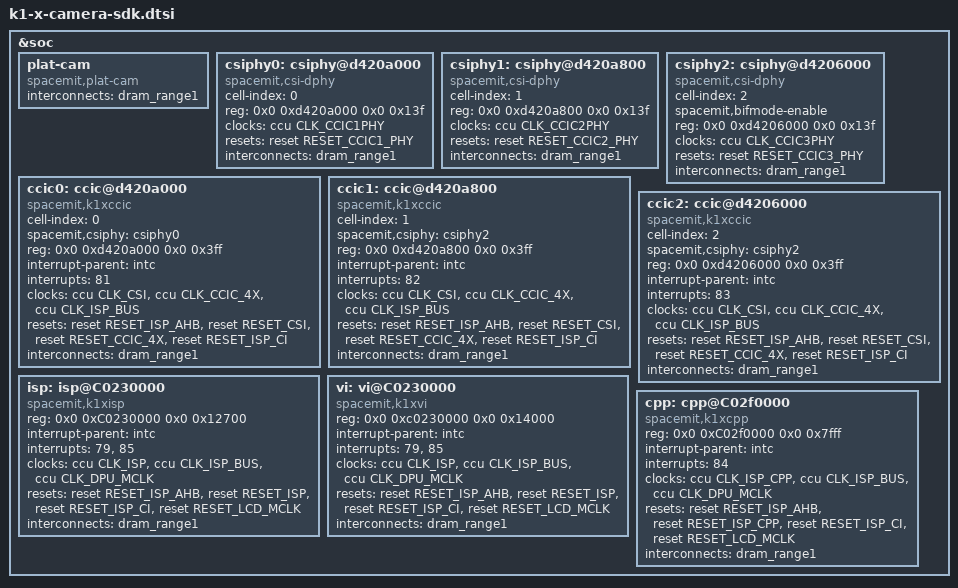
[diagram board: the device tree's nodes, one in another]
// SPDX-License-Identifier: GPL-2.0
/*
 * Copyright (C) 2023 SPACEMIT Micro Limited
 */

//#include "k1-x-camera-reserved-mm.dtsi"
#include "k1-x-camera-sensor.dtsi"

&soc {
	plat-cam {
		compatible = "spacemit,plat-cam", "simple-bus";
		#address-cells = <2>;
		#size-cells = <2>;
		interconnects = <&dram_range1>;
		interconnect-names = "dma-mem";
		status = "okay";
	};

	csiphy0: csiphy@d420a000 {
		compatible = "spacemit,csi-dphy";
		cell-index = <0>;
		reg = <0x0 0xd420a000 0x0 0x13f>;
		reg-names = "csiphy-regs";
		clocks = <&ccu CLK_CCIC1PHY>;
		clock-names = "csi_dphy";
		resets = <&reset RESET_CCIC1_PHY>;
		reset-names = "cphy_reset";
		interconnects = <&dram_range1>;
		interconnect-names = "dma-mem";
		status = "okay";
	};

	csiphy1: csiphy@d420a800 {
		compatible = "spacemit,csi-dphy";
		cell-index = <1>;
		reg = <0x0 0xd420a800 0x0 0x13f>;
		reg-names = "csiphy-regs";
		clocks = <&ccu CLK_CCIC2PHY>;
		clock-names = "csi_dphy";
		resets = <&reset RESET_CCIC2_PHY>;
		reset-names = "cphy_reset";
		interconnects = <&dram_range1>;
		interconnect-names = "dma-mem";
		status = "okay";
	};

	csiphy2: csiphy@d4206000 {
		compatible = "spacemit,csi-dphy";
		cell-index = <2>;
		spacemit,bifmode-enable;
		reg = <0x0 0xd4206000 0x0 0x13f>;
		reg-names = "csiphy-regs";
		clocks = <&ccu CLK_CCIC3PHY>;
		clock-names = "csi_dphy";
		resets = <&reset RESET_CCIC3_PHY>;
		reset-names = "cphy_reset";
		interconnects = <&dram_range1>;
		interconnect-names = "dma-mem";
		status = "okay";
	};

	ccic0: ccic@d420a000 {
		compatible = "spacemit,k1xccic";
		cell-index = <0>;
		spacemit,csiphy = <&csiphy0>;
		reg = <0x0 0xd420a000 0x0 0x3ff>;
		reg-names = "ccic-regs";
		interrupt-parent = <&intc>;
		interrupts = <81>;
		interrupt-names = "ipe-irq";
		clocks = <&ccu CLK_CSI>,
				<&ccu CLK_CCIC_4X>,
				<&ccu CLK_ISP_BUS>;
		clock-names = "csi_func", "ccic_func", "isp_axi";
		resets = <&reset RESET_ISP_AHB>, <&reset RESET_CSI>,
				<&reset RESET_CCIC_4X>, <&reset RESET_ISP_CI>;
		reset-names = "isp_ahb_reset", "csi_reset",
				"ccic_4x_reset", "isp_ci_reset";
		interconnects = <&dram_range1>;
		interconnect-names = "dma-mem";
		status = "okay";
	};

	ccic1: ccic@d420a800 {
		compatible = "spacemit,k1xccic";
		cell-index = <1>;
		spacemit,csiphy = <&csiphy2>;
		reg = <0x0 0xd420a800 0x0 0x3ff>;
		reg-names = "ccic-regs";
		interrupt-parent = <&intc>;
		interrupts = <82>;
		interrupt-names = "ipe-irq";
		clocks = <&ccu CLK_CSI>, <&ccu CLK_CCIC_4X>,
				<&ccu CLK_ISP_BUS>;
		clock-names = "csi_func", "ccic_func",
				"isp_axi";
		resets = <&reset RESET_ISP_AHB>, <&reset RESET_CSI>,
				<&reset RESET_CCIC_4X>, <&reset RESET_ISP_CI>;
		reset-names = "isp_ahb_reset", "csi_reset",
				"ccic_4x_reset", "isp_ci_reset";
		interconnects = <&dram_range1>;
		interconnect-names = "dma-mem";
		status = "okay";
	};

	ccic2: ccic@d4206000 {
		compatible = "spacemit,k1xccic";
		cell-index = <2>;
		spacemit,csiphy = <&csiphy2>;
		reg = <0x0 0xd4206000 0x0 0x3ff>;
		reg-names = "ccic-regs";
		interrupt-parent = <&intc>;
		interrupts = <83>;
		interrupt-names = "ipe-irq";
		clocks = <&ccu CLK_CSI>, <&ccu CLK_CCIC_4X>,
				<&ccu CLK_ISP_BUS>;
		clock-names = "csi_func", "ccic_func",
				"isp_axi";
		resets = <&reset RESET_ISP_AHB>, <&reset RESET_CSI>,
				<&reset RESET_CCIC_4X>, <&reset RESET_ISP_CI>;
		reset-names = "isp_ahb_reset", "csi_reset",
				"ccic_4x_reset", "isp_ci_reset";
		interconnects = <&dram_range1>;
		interconnect-names = "dma-mem";
		status = "okay";
	};

	isp: isp@C0230000 {
		compatible = "spacemit,k1xisp";
		reg = <0x0 0xC0230000 0x0 0x12700>;
		reg-names = "isp";
		interrupt-parent = <&intc>;
		interrupts = <79>, <85>;
		interrupt-names = "feisp-irq", "feisp-dma-irq";
		clocks = <&ccu CLK_ISP>,
				<&ccu CLK_ISP_BUS>,
				<&ccu CLK_DPU_MCLK>;
		clock-names = "isp_func", "isp_axi", "dpu_mclk";
		resets = <&reset RESET_ISP_AHB>, <&reset RESET_ISP>,
				<&reset RESET_ISP_CI>, <&reset RESET_LCD_MCLK>;
		reset-names = "isp_ahb_reset", "isp_reset",
				"isp_ci_reset", "lcd_mclk_reset";
		interconnects = <&dram_range1>;
		interconnect-names = "dma-mem";
		status = "okay";
	};

	vi: vi@C0230000 {
		compatible = "spacemit,k1xvi";
		reg = <0x0 0xc0230000 0x0 0x14000>;
		reg-names = "vi";
		interrupt-parent = <&intc>;
		interrupts = <79>, <85>;
		interrupt-names = "feisp-irq", "feisp-dma-irq";
		clocks = <&ccu CLK_ISP>, <&ccu CLK_ISP_BUS>,
				<&ccu CLK_DPU_MCLK>;
		clock-names = "isp_func", "isp_axi",
				"dpu_mclk";
		resets = <&reset RESET_ISP_AHB>, <&reset RESET_ISP>,
				<&reset RESET_ISP_CI>, <&reset RESET_LCD_MCLK>;
		reset-names = "isp_ahb_reset", "isp_reset",
				"isp_ci_reset", "lcd_mclk_reset";
		interconnects = <&dram_range1>;
		interconnect-names = "dma-mem";
		status = "okay";
	};

	cpp: cpp@C02f0000 {
		compatible = "spacemit,k1xcpp";
		reg = <0x0 0xC02f0000 0x0 0x7fff>;
		reg-names = "cpp";
		interrupt-parent = <&intc>;
		interrupts = <84>;
		interrupt-names = "cpp";
		clocks = <&ccu CLK_ISP_CPP>, <&ccu CLK_ISP_BUS>,
				<&ccu CLK_DPU_MCLK>;
		clock-names = "cpp_func", "isp_axi",
				"dpu_mclk";
		resets = <&reset RESET_ISP_AHB>, <&reset RESET_ISP_CPP>,
				<&reset RESET_ISP_CI>, <&reset RESET_LCD_MCLK>;
		reset-names = "isp_ahb_reset", "isp_cpp_reset",
				"isp_ci_reset", "lcd_mclk_reset";
		interconnects = <&dram_range1>;
		interconnect-names = "dma-mem";
		status = "okay";
	};
}; /* soc */
